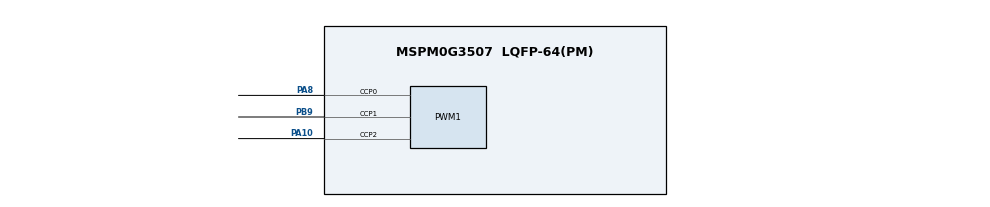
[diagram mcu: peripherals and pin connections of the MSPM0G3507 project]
/**
 * These arguments were used when this file was generated. They will be automatically applied on subsequent loads
 * via the GUI or CLI. Run CLI with '--help' for additional information on how to override these arguments.
 * @cliArgs --device "MSPM0G350X" --part "Default" --package "LQFP-64(PM)" --product "mspm0_sdk@2.09.00.02"
 * @v2CliArgs --device "MSPM0G3507" --package "LQFP-64(PM)" --product "mspm0_sdk@2.09.00.02"
 * @versions {"tool":"1.26.0+4407"}
 */

/**
 * Import the modules used in this configuration.
 */
const ADC12  = scripting.addModule("/ti/driverlib/ADC12", {}, false);
const ADC121 = ADC12.addInstance();
const ADC122 = ADC12.addInstance();
const PWM    = scripting.addModule("/ti/driverlib/PWM", {}, false);
const PWM1   = PWM.addInstance();
const SYSCTL = scripting.addModule("/ti/driverlib/SYSCTL");

/**
 * Write custom configuration values to the imported modules.
 */
ADC121.$name                      = "ADC12_0";
ADC121.trigSrc                    = "DL_ADC12_TRIG_SRC_EVENT";
ADC121.subChanID                  = 1;
ADC121.samplingOperationMode      = "sequence";
ADC121.endAdd                     = 1;
ADC121.enabledInterrupts          = ["DL_ADC12_INTERRUPT_MEM1_RESULT_LOADED"];
ADC121.repeatMode                 = true;
ADC121.disChan12                  = true;
ADC121.adcMem1chansel             = "DL_ADC12_INPUT_CHAN_1";
ADC121.adcPin0Config.$name        = "ti_driverlib_gpio_GPIOPinGeneric4";
ADC121.peripheral.$assign         = "ADC1";
ADC121.peripheral.adcPin0.$assign = "PA15";
ADC121.adcPin1Config.$name        = "ti_driverlib_gpio_GPIOPinGeneric6";

ADC122.$name                      = "ADC12_1";
ADC122.trigSrc                    = "DL_ADC12_TRIG_SRC_EVENT";
ADC122.subChanID                  = 2;
ADC122.samplingOperationMode      = "sequence";
ADC122.repeatMode                 = true;
ADC122.disChan12                  = true;
ADC122.endAdd                     = 2;
ADC122.adcMem2chansel             = "DL_ADC12_INPUT_CHAN_6";
ADC122.adcMem1chansel             = "DL_ADC12_INPUT_CHAN_3";
ADC122.adcMem0chansel             = "DL_ADC12_INPUT_CHAN_5";
ADC122.adcPin6Config.$name        = "ti_driverlib_gpio_GPIOPinGeneric9";
ADC122.adcPin3Config.$name        = "ti_driverlib_gpio_GPIOPinGeneric5";
ADC122.peripheral.$assign         = "ADC0";
ADC122.peripheral.adcPin3.$assign = "PA24";
ADC122.peripheral.adcPin6.$assign = "PB20";
ADC122.adcPin5Config.$name        = "ti_driverlib_gpio_GPIOPinGeneric7";

const Board = scripting.addModule("/ti/driverlib/Board", {}, false);

PWM1.$name                           = "PWM_0";
PWM1.timerCount                      = 133;
PWM1.ccIndexCmpl                     = [0,1];
PWM1.deadBandEn                      = true;
PWM1.dbFallDelayTimerCount           = 3;
PWM1.dbRiseDelayTimerCount           = 3;
PWM1.pwmMode                         = "EDGE_ALIGN_UP";
PWM1.ccIndex                         = [0,1,2];
PWM1.event1PublisherChannel          = 1;
PWM1.event1ControllerInterruptEn     = ["CC2_UP_EVENT"];
PWM1.event2PublisherChannel          = 2;
PWM1.event2ControllerInterruptEn     = ["CC2_UP_EVENT"];
PWM1.PWM_CHANNEL_0.$name             = "ti_driverlib_pwm_PWMTimerCC0";
PWM1.PWM_CHANNEL_0.dutyCycle         = 70;
PWM1.PWM_CHANNEL_1.$name             = "ti_driverlib_pwm_PWMTimerCC1";
PWM1.PWM_CHANNEL_1.dutyCycle         = 40;
PWM1.ccp0PinConfig.$name             = "ti_driverlib_gpio_GPIOPinGeneric0";
PWM1.ccp1PinConfig.$name             = "ti_driverlib_gpio_GPIOPinGeneric1";
PWM1.ccp0Pin_cmplConfig.$name        = "ti_driverlib_gpio_GPIOPinGeneric2";
PWM1.ccp1Pin_cmplConfig.$name        = "ti_driverlib_gpio_GPIOPinGeneric3";
PWM1.peripheral.ccp0Pin.$assign      = "PA8";
PWM1.peripheral.ccp0Pin_cmpl.$assign = "PA22";
PWM1.peripheral.ccp1Pin.$assign      = "PB9";
PWM1.peripheral.ccp1Pin_cmpl.$assign = "PA25";
PWM1.peripheral.ccp2Pin.$assign      = "PA10";
PWM1.PWM_CHANNEL_2.$name             = "ti_driverlib_pwm_PWMTimerCC2";
PWM1.ccp2PinConfig.$name             = "ti_driverlib_gpio_GPIOPinGeneric8";

SYSCTL.forceDefaultClkConfig = true;
SYSCTL.HSCLKSource           = "HFCLK";

/**
 * Pinmux solution for unlocked pins/peripherals. This ensures that minor changes to the automatic solver in a future
 * version of the tool will not impact the pinmux you originally saw.  These lines can be completely deleted in order to
 * re-solve from scratch.
 */
ADC121.peripheral.adcPin1.$suggestSolution = "PA16";
ADC122.peripheral.adcPin5.$suggestSolution = "PB24";
Board.peripheral.$suggestSolution          = "DEBUGSS";
Board.peripheral.swclkPin.$suggestSolution = "PA20";
Board.peripheral.swdioPin.$suggestSolution = "PA19";
PWM1.peripheral.$suggestSolution           = "TIMA0";
SYSCTL.peripheral.$suggestSolution         = "SYSCTL";
